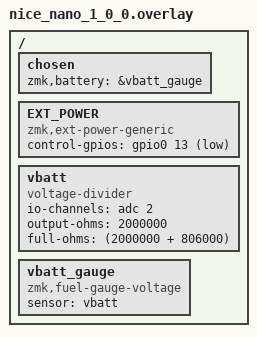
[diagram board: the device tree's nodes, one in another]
/*
 * Copyright (c) 2025 The ZMK Contributors
 *
 * SPDX-License-Identifier: MIT
 */

/ {
    chosen {
        zmk,battery = &vbatt_gauge;
    };

    // Node name must match original "EXT_POWER" label to preserve user settings.
    EXT_POWER {
        compatible = "zmk,ext-power-generic";
        control-gpios = <&gpio0 13 GPIO_ACTIVE_LOW>;
    };

    vbatt: vbatt {
        compatible = "voltage-divider";
        io-channels = <&adc 2>;
        output-ohms = <2000000>;
        full-ohms = <(2000000 + 806000)>;
    };

    vbatt_gauge: vbatt_gauge {
        compatible = "zmk,fuel-gauge-voltage";
        sensor = <&vbatt>;
    };
};
